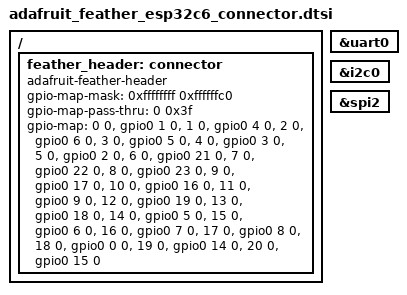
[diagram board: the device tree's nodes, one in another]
/*
 * Copyright (c) 2020 Richard Osterloh <richard.osterloh@gmail.com>
 * Copyright (c) 2024 Leon Rinkel <leon@rinkel.me>
 * Copyright (c) 2025 Philipp Steiner <philipp.steiner1987@gmail.com>
 * Copyright (c) 2026 Hong Nguyen <hong.nguyen.k54@gmail.com>
 *
 * SPDX-License-Identifier: Apache-2.0
 */

/ {
	feather_header: connector {
		compatible = "adafruit-feather-header";
		#gpio-cells = <2>;
		gpio-map-mask = <0xffffffff 0xffffffc0>;
		gpio-map-pass-thru = <0 0x3f>;
		gpio-map = <0 0 &gpio0 1 0>,	/* A0 */
			   <1 0 &gpio0 4 0>,	/* A1 */
			   <2 0 &gpio0 6 0>,	/* A2 */
			   <3 0 &gpio0 5 0>,	/* A3 */
			   <4 0 &gpio0 3 0>,	/* A4 */
			   <5 0 &gpio0 2 0>,	/* A5 */
			   <6 0 &gpio0 21 0>,	/* SCK */
			   <7 0 &gpio0 22 0>,	/* MOSI */
			   <8 0 &gpio0 23 0>,	/* MISO */
			   <9 0 &gpio0 17 0>,	/* RX */
			   <10 0 &gpio0 16 0>,	/* TX */
			   <11 0 &gpio0 9 0>,	/* D9 */
			   <12 0 &gpio0 19 0>,	/* SDA */
			   <13 0 &gpio0 18 0>,	/* SCL */
			   <14 0 &gpio0 5 0>,	/* D5 */
			   <15 0 &gpio0 6 0>,	/* D6 */
			   <16 0 &gpio0 7 0>,	/* D7 */
			   <17 0 &gpio0 8 0>,	/* D8 */
			   <18 0 &gpio0 0 0>,	/* D0 */
			   <19 0 &gpio0 14 0>,	/* D14 */
			   <20 0 &gpio0 15 0>;	/* D15 */
	};
};

feather_serial: &uart0 {};

feather_i2c: &i2c0 {};

feather_spi: &spi2 {};
